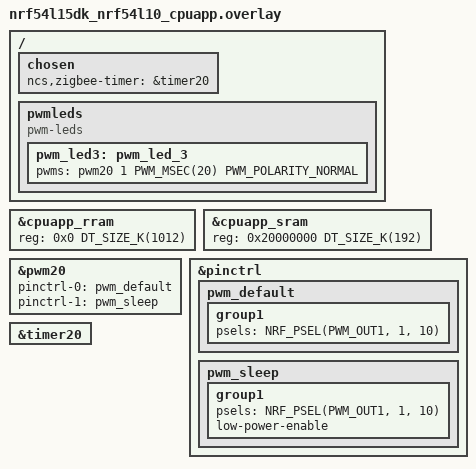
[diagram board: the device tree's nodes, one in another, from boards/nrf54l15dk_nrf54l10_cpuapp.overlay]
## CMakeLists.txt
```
#
# Copyright (c) 2024 Nordic Semiconductor ASA
#
# SPDX-License-Identifier: LicenseRef-Nordic-5-Clause
#

cmake_minimum_required(VERSION 3.20.0)

find_package(Zephyr REQUIRED HINTS $ENV{ZEPHYR_BASE})

project("Zigbee coordinator")

# NORDIC SDK APP START
target_sources(app PRIVATE
  src/main.c
  src/zboss_mem_globals.c
)

target_include_directories(app PRIVATE include)
# NORDIC SDK APP END

# LTO link: zb_memconfig.o from prebuilts is plain ELF (weak gc_*); strong gc_*
# in zb_mem_config_context.h must not be LTO bytecode or ld warns about symbol size.
if(CONFIG_LTO)
	set_source_files_properties(
		src/zboss_mem_globals.c
		PROPERTIES COMPILE_OPTIONS -fno-lto
	)
endif()
```

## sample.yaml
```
sample:
  description: Zigbee Light control - coordinator sample
  name: Zigbee Network coordinator
common:
  tags:
    - ci_build
    - smoke
    - sysbuild
    - ci_samples_zigbee
tests:
  sample.zigbee.network_coordinator:
    sysbuild: true
    build_only: true
    integration_platforms:
      - nrf5340dk/nrf5340/cpuapp
      - nrf54l15dk/nrf54l15/cpuapp
      - nrf54lc10dk/nrf54lc10a/cpuapp
      - nrf54lm20dk/nrf54lm20b/cpuapp
    platform_allow:
      - nrf52840dk/nrf52840
      - nrf5340dk/nrf5340/cpuapp
      - nrf54l15dk/nrf54l10/cpuapp
      - nrf54l15dk/nrf54l15/cpuapp
      - nrf54lc10dk/nrf54lc10a/cpuapp
      - nrf54lm20dk/nrf54lm20a/cpuapp
      - nrf54lm20dk/nrf54lm20b/cpuapp
  sample.zigbee.network_coordinator.demo_commissioning:
    sysbuild: true
    build_only: true
    extra_args:
      - SNIPPET=zigbee_demo_commissioning
    integration_platforms:
      - nrf54l15dk/nrf54l15/cpuapp
    platform_allow:
      - nrf52840dk/nrf52840
      - nrf5340dk/nrf5340/cpuapp
      - nrf54l15dk/nrf54l10/cpuapp
      - nrf54l15dk/nrf54l15/cpuapp
      - nrf54lc10dk/nrf54lc10a/cpuapp
      - nrf54lm20dk/nrf54lm20a/cpuapp
      - nrf54lm20dk/nrf54lm20b/cpuapp
```

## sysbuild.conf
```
#
# Copyright (c) 2026 Nordic Semiconductor ASA
#
# SPDX-License-Identifier: LicenseRef-Nordic-5-Clause
#

# Disable partition manager
SB_CONFIG_PARTITION_MANAGER=n
```

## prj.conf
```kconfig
#
# Copyright (c) 2024 Nordic Semiconductor ASA
#
# SPDX-License-Identifier: LicenseRef-Nordic-5-Clause
#

CONFIG_NCS_SAMPLES_DEFAULTS=y

CONFIG_UART_INTERRUPT_DRIVEN=y
CONFIG_SERIAL=y
CONFIG_GPIO=y

# Make sure printk is not printing to the UART console
CONFIG_CONSOLE=y
CONFIG_UART_CONSOLE=y

CONFIG_HEAP_MEM_POOL_SIZE=2048
CONFIG_MAIN_THREAD_PRIORITY=7

CONFIG_ZIGBEE_ADD_ON=y
CONFIG_ZIGBEE_APP_UTILS=y
CONFIG_ZIGBEE_ROLE_COORDINATOR=y

# Enable DK LED and Buttons library
CONFIG_DK_LIBRARY=y
```

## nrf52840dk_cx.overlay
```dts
/* Copyright (c) 2024 Nordic Semiconductor ASA
 *
 * SPDX-License-Identifier: LicenseRef-Nordic-5-Clause
 */

/ {
  radio_coex: radio_coex_three_wire {
    status = "okay";
    compatible = "generic-radio-coex-three-wire";
    req-gpios =     <&gpio0 14 (GPIO_PULL_DOWN | GPIO_ACTIVE_HIGH)>;
    pri-dir-gpios = <&gpio0 16 (GPIO_PULL_UP   | GPIO_ACTIVE_HIGH)>;
    grant-gpios =   <&gpio0 12 (GPIO_PULL_DOWN | GPIO_ACTIVE_HIGH)>;
  };
};

&radio {
  coex = <&radio_coex>;
};
```

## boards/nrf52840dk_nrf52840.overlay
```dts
/*
 * Copyright (c) 2024 Nordic Semiconductor ASA
 *
 * SPDX-License-Identifier: LicenseRef-Nordic-5-Clause
 */
/ {
	chosen {
		ncs,zigbee-timer = &timer2;
	};
};

&timer2 {
	status = "okay";
};
```

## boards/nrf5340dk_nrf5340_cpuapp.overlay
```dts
/*
 * Copyright (c) 2025 Nordic Semiconductor ASA
 *
 * SPDX-License-Identifier: LicenseRef-Nordic-5-Clause
 */

#include <nrf5340_cpuapp_partitions.dtsi>

/ {
	chosen {
		ncs,zigbee-timer = &timer2;
	};
};

&timer2 {
	status = "okay";
};
```

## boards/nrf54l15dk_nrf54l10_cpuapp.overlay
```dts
/*
 * Copyright (c) 2024 Nordic Semiconductor ASA
 *
 * SPDX-License-Identifier: LicenseRef-Nordic-5-Clause
 */


/ {

	chosen {
		ncs,zigbee-timer = &timer20;
	};

	pwmleds {
		compatible = "pwm-leds";
		pwm_led3: pwm_led_3 {
			pwms = <&pwm20 1 PWM_MSEC(20) PWM_POLARITY_NORMAL>;
		};
	};
};

// restore full RRAM and SRAM space - by default some parts are dedicated to FLPR
&cpuapp_rram {
	reg = <0x0 DT_SIZE_K(1012)>;
};

&cpuapp_sram {
	reg = <0x20000000 DT_SIZE_K(192)>;
	ranges = <0x0 0x20000000  DT_SIZE_K(192)>;
};

&pwm20 {
	status = "okay";
	pinctrl-0 = <&pwm_default>;
	pinctrl-1 = <&pwm_sleep>;
	pinctrl-names = "default", "sleep";
};

&pinctrl {
	pwm_default: pwm_default {
		group1 {
			psels = <NRF_PSEL(PWM_OUT1, 1, 10)>;
		};
	};
	pwm_sleep: pwm_sleep {
		group1 {
			psels = <NRF_PSEL(PWM_OUT1, 1, 10)>;
			low-power-enable;
		};
	};
};

&timer20 {
	status = "okay";
};
```

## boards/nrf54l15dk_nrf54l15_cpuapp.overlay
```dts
/*
 * Copyright (c) 2024 Nordic Semiconductor ASA
 *
 * SPDX-License-Identifier: LicenseRef-Nordic-5-Clause
 */

#include <nrf54l15_cpuapp_partitions.dtsi>

/ {
	chosen {
		ncs,zigbee-timer = &timer20;
	};

	pwmleds {
		compatible = "pwm-leds";

		pwm_led1: pwm_led_1 {
			pwms = <&pwm20 1 PWM_MSEC(20) PWM_POLARITY_NORMAL>;
		};
	};
};

&pwm20 {
	status = "okay";
	pinctrl-0 = <&pwm_default>;
	pinctrl-1 = <&pwm_sleep>;
	pinctrl-names = "default", "sleep";
};

&pinctrl {
	pwm_default: pwm_default {
		group1 {
			psels = <NRF_PSEL(PWM_OUT1, 1, 10)>;
		};
	};

	pwm_sleep: pwm_sleep {
		group1 {
			psels = <NRF_PSEL(PWM_OUT1, 1, 10)>;
			low-power-enable;
		};
	};
};

&timer20 {
	status = "okay";
};
```

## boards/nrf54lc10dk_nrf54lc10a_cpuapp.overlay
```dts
/*
 * Copyright (c) 2026 Nordic Semiconductor ASA
 *
 * SPDX-License-Identifier: LicenseRef-Nordic-5-Clause
 */

#include <nrf54lc10_cpuapp_partitions.dtsi>

/ {
	chosen {
		ncs,zigbee-timer = &timer20;
	};
};

&timer20 {
	status = "okay";
};
```

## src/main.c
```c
/*
 * Copyright (c) 2024 Nordic Semiconductor ASA
 *
 * SPDX-License-Identifier: LicenseRef-Nordic-5-Clause
 */

/** @file
 *  @brief Simple Zigbee network coordinator implementation
 */

#include <zephyr/kernel.h>
#include <zephyr/device.h>
#include <zephyr/logging/log.h>
#include <dk_buttons_and_leds.h>

#include <zboss_api.h>
#include <zigbee/zigbee_error_handler.h>
#include <zigbee/zigbee_app_utils.h>
#include <zigbee/zigbee_app_io_shell.h>
#include <zb_nrf_platform.h>


#define RUN_STATUS_LED                         DK_LED1
#define RUN_LED_BLINK_INTERVAL                 1000

/* Device endpoint, used to receive ZCL commands. */
#define ZIGBEE_COORDINATOR_ENDPOINT            10

/* Type of power sources available for the device.
 * For possible values see section 3.2.2.2.8 of ZCL specification.
 */
#define COORDINATOR_INIT_BASIC_POWER_SOURCE    ZB_ZCL_BASIC_POWER_SOURCE_DC_SOURCE

/* LED indicating that device successfully joined Zigbee network. */
#define ZIGBEE_NETWORK_STATE_LED               DK_LED3

/* LED used for device identification. */
#define IDENTIFY_LED                           DK_LED4

/* Button which reopens the Zigbee Network. */
#define KEY_ZIGBEE_NETWORK_REOPEN              DK_BTN1_MSK

/* Button used to enter the Identify mode. */
#define IDENTIFY_MODE_BUTTON                   DK_BTN4_MSK

/* If set to ZB_TRUE then device will not open the network after forming or reboot. */
#define ZIGBEE_MANUAL_STEERING                 ZB_FALSE

#define ZIGBEE_PERMIT_LEGACY_DEVICES           ZB_FALSE

#ifndef ZB_COORDINATOR_ROLE
#error Define ZB_COORDINATOR_ROLE to compile coordinator source code.
#endif

/* Button to start Factory Reset */
#define FACTORY_RESET_BUTTON IDENTIFY_MODE_BUTTON

LOG_MODULE_REGISTER(app, LOG_LEVEL_INF);

/* Main application customizable context.
 * Stores all settings and static values.
 */
struct zb_device_ctx {
	zb_zcl_basic_attrs_t basic_attr;
	zb_zcl_identify_attrs_t identify_attr;
};

/* Zigbee device application context storage. */
static struct zb_device_ctx dev_ctx;

ZB_ZCL_DECLARE_IDENTIFY_ATTRIB_LIST(
	identify_attr_list,
	&dev_ctx.identify_attr.identify_time);

ZB_ZCL_DECLARE_BASIC_ATTRIB_LIST(
	basic_attr_list,
	&dev_ctx.basic_attr.zcl_version,
	&dev_ctx.basic_attr.power_source);

ZB_HA_DECLARE_RANGE_EXTENDER_CLUSTER_LIST(
	nwk_coordinator_clusters,
	basic_attr_list,
	identify_attr_list);

ZB_HA_DECLARE_RANGE_EXTENDER_EP(
	nwk_coordinator_ep,
	ZIGBEE_COORDINATOR_ENDPOINT,
	nwk_coordinator_clusters);

ZBOSS_DECLARE_DEVICE_CTX_1_EP(
	nwk_coordinator,
	nwk_coordinator_ep);


/**@brief Function for initializing all clusters attributes. */
static void app_clusters_attr_init(void)
{
	/* Basic cluster attributes data. */
	dev_ctx.basic_attr.zcl_version = ZB_ZCL_VERSION;
	dev_ctx.basic_attr.power_source = COORDINATOR_INIT_BASIC_POWER_SOURCE;

	/* Identify cluster attributes data. */
	dev_ctx.identify_attr.identify_time = ZB_ZCL_IDENTIFY_IDENTIFY_TIME_DEFAULT_VALUE;
}

/**@brief Function to toggle the identify LED.
 *
 * @param  param  Callback parameter, required by ZBOSS scheduler API.
 */
static void toggle_identify_led(zb_cb_param_t param)
{
	static int blink_status;

	zigbee_app_io_set_led(IDENTIFY_LED, (++blink_status) % 2);
	ZB_SCHEDULE_APP_ALARM(toggle_identify_led, param, ZB_MILLISECONDS_TO_BEACON_INTERVAL(100));
}

/**@brief Function to handle identify notification events on the first endpoint.
 *
 * @param  param  ZB_TRUE when identify starts, ZB_FALSE when it stops.
 */
static void identify_cb(zb_cb_param_t param)
{
	zb_ret_t zb_err_code;

	if (param) {
		/* Schedule a self-scheduling function that will toggle the LED. */
		ZB_SCHEDULE_APP_CALLBACK(toggle_identify_led, param);
	} else {
		/* Cancel the toggling function alarm and turn off LED. */
		zb_err_code = ZB_SCHEDULE_APP_ALARM_CANCEL(toggle_identify_led, ZB_ALARM_ANY_PARAM);
		ZVUNUSED(zb_err_code);

		zigbee_app_io_set_led(IDENTIFY_LED, 0);
	}
}

/**@brief Starts identifying the device.
 *
 * @param  param  Unused parameter, required by ZBOSS scheduler API.
 */
static void start_identifying(zb_cb_param_t param)
{
	ZVUNUSED(param);

	if (ZB_JOINED()) {
		/* Check if endpoint is in identifying mode,
		 * if not, put desired endpoint in identifying mode.
		 */
		if (dev_ctx.identify_attr.identify_time ==
		    ZB_ZCL_IDENTIFY_IDENTIFY_TIME_DEFAULT_VALUE) {

			zb_ret_t zb_err_code = zb_bdb_finding_binding_target(
				ZIGBEE_COORDINATOR_ENDPOINT);

			if (zb_err_code == RET_OK) {
				LOG_INF("Enter identify mode");
			} else if (zb_err_code == RET_INVALID_STATE) {
				LOG_WRN("RET_INVALID_STATE - Cannot enter identify mode");
			} else {
				ZB_ERROR_CHECK(zb_err_code);
			}
		} else {
			LOG_INF("Cancel identify mode");
			zb_bdb_finding_binding_target_cancel();
		}
	} else {
		LOG_WRN("Device not in a network - cannot enter identify mode");
	}
}

/**@brief Callback used in order to visualise network steering period.
 *
 * @param[in]   param   Not used. Required by callback type definition.
 */
static void steering_finished(zb_cb_param_t param)
{
	ARG_UNUSED(param);

	LOG_INF("Network steering finished");
	zigbee_app_io_set_led_off(ZIGBEE_NETWORK_STATE_LED);
}

/**@brief Callback for button events.
 *
 * @param[in]   button_state  Bitmask containing buttons state.
 * @param[in]   has_changed   Bitmask containing buttons that has changed their state.
 */
static void button_changed(uint32_t button_state, uint32_t has_changed)
{
	/* Calculate bitmask of buttons that are pressed and have changed their state. */
	uint32_t buttons = button_state & has_changed;
	zb_bool_t comm_status;

	if (buttons & KEY_ZIGBEE_NETWORK_REOPEN) {
		(void)(ZB_SCHEDULE_APP_ALARM_CANCEL(steering_finished, ZB_ALARM_ANY_PARAM));

		comm_status = bdb_start_top_level_commissioning(ZB_BDB_NETWORK_STEERING);
		if (comm_status) {
			LOG_INF("Top level commissioning restated");
		} else {
			LOG_INF("Top level commissioning hasn't finished yet!");
		}
	}

	if (IDENTIFY_MODE_BUTTON & has_changed) {
		if (IDENTIFY_MODE_BUTTON & button_state) {
			/* Button changed its state to pressed */
		} else {
			/* Button changed its state to released */
			if (was_factory_reset_done()) {
				/* The long press was for Factory Reset */
				LOG_DBG("After Factory Reset - ignore button release");
			} else   {
				/* Button released before Factory Reset */

				/* Start identification mode */
				ZB_SCHEDULE_APP_CALLBACK(start_identifying, 0);
			}
		}
	}

	check_factory_reset_button(button_state, has_changed);
}

/**@brief Function for initializing LEDs and Buttons. */
static void configure_gpio(void)
{
	int err;

	err = dk_buttons_init(button_changed);
	if (err) {
		LOG_ERR("Cannot init buttons (err: %d)", err);
	}

	err = dk_leds_init();
	if (err) {
		LOG_ERR("Cannot init LEDs (err: %d)", err);
	}

	zigbee_app_io_shell_init(button_changed);
}

/**@brief Zigbee stack event handler.
 *
 * @param[in]   param   Reference to the Zigbee stack buffer used to pass signal.
 */
void zboss_signal_handler(zb_cb_param_t param)
{
	/* Read signal description out of memory buffer. */
	zb_zdo_app_signal_hdr_t *sg_p = NULL;
	zb_zdo_app_signal_type_t sig = zb_get_app_signal(param, &sg_p);
	zb_ret_t status = ZB_GET_APP_SIGNAL_STATUS(param);
	zb_ret_t zb_err_code;
	zb_bool_t comm_status;
	zb_time_t timeout_bi;

	switch (sig) {
	case ZB_BDB_SIGNAL_DEVICE_REBOOT:
		/* BDB initialization completed after device reboot,
		 * use NVRAM contents during initialization.
		 * Device joined/rejoined and started.
		 */
		if (status == RET_OK) {
			if (ZIGBEE_MANUAL_STEERING == ZB_FALSE) {
				LOG_INF("Start network steering");
				comm_status = bdb_start_top_level_commissioning(
					ZB_BDB_NETWORK_STEERING);
				ZB_COMM_STATUS_CHECK(comm_status);
			} else {
				LOG_INF("Coordinator restarted successfully");
			}
		} else {
			LOG_ERR("Failed to initialize Zigbee stack using NVRAM data (status: %d)",
				status);
		}
		break;

	case ZB_BDB_SIGNAL_STEERING:
		if (status == RET_OK) {
			if (ZIGBEE_PERMIT_LEGACY_DEVICES == ZB_TRUE) {
				LOG_INF("Allow pre-Zigbee 3.0 devices to join the network");
				zb_bdb_set_legacy_device_support(1);
			}

			/* Schedule an alarm to notify about the end of steering period.
			 */
			LOG_INF("Network steering started");
			zb_err_code = ZB_SCHEDULE_APP_ALARM(
				steering_finished, 0,
				ZB_TIME_ONE_SECOND *
				ZB_ZGP_DEFAULT_COMMISSIONING_WINDOW);
			ZB_ERROR_CHECK(zb_err_code);
		}
		break;

	case ZB_ZDO_SIGNAL_DEVICE_ANNCE: {
		zb_zdo_signal_device_annce_params_t *dev_annce_params =
			ZB_ZDO_SIGNAL_GET_PARAMS(
				sg_p, zb_zdo_signal_device_annce_params_t);

		LOG_INF("New device commissioned or rejoined (short: 0x%04hx)",
			dev_annce_params->device_short_addr);

		zb_err_code = ZB_SCHEDULE_APP_ALARM_CANCEL(steering_finished, ZB_ALARM_ANY_PARAM);
		if (zb_err_code == RET_OK) {
			LOG_INF("Joining period extended.");
			zb_err_code = ZB_SCHEDULE_APP_ALARM(
				steering_finished, 0,
				ZB_TIME_ONE_SECOND *
				ZB_ZGP_DEFAULT_COMMISSIONING_WINDOW);
			ZB_ERROR_CHECK(zb_err_code);
		}
	} break;

	default:
		/* Call default signal handler. */
		ZB_ERROR_CHECK(zigbee_default_signal_handler(param));
		break;
	}

	/* Update network status LED. */
	if (ZB_JOINED() &&
	    (ZB_SCHEDULE_GET_ALARM_TIME(steering_finished, ZB_ALARM_ANY_PARAM,
					&timeout_bi) == RET_OK)) {
		zigbee_app_io_set_led_on(ZIGBEE_NETWORK_STATE_LED);
	} else {
		zigbee_app_io_set_led_off(ZIGBEE_NETWORK_STATE_LED);
	}

	/*
	 * All callbacks should either reuse or free passed buffers.
	 * If param == 0, the buffer is invalid (not passed).
	 */
	if (param) {
		zb_buf_free(param);
	}
}

int main(void)
{
	int blink_status = 0;

	LOG_INF("Starting Zigbee R23 Network Coordinator application");

	/* Initialize */
	configure_gpio();
	register_factory_reset_button(FACTORY_RESET_BUTTON);

	/* Register device context (endpoints). */
	ZB_AF_REGISTER_DEVICE_CTX(&nwk_coordinator);

	app_clusters_attr_init();

	/* Register handlers to identify notifications. */
	ZB_AF_SET_IDENTIFY_NOTIFICATION_HANDLER(ZIGBEE_COORDINATOR_ENDPOINT, identify_cb);

	/* Start Zigbee default thread */
	zigbee_enable();

	LOG_INF("Zigbee R23 Network Coordinator application started");

	while (1) {
		zigbee_app_io_set_led(RUN_STATUS_LED, (++blink_status) % 2);
		k_sleep(K_MSEC(RUN_LED_BLINK_INTERVAL));
	}
}
```

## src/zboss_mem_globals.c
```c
/*
 * Copyright (c) 2026 Nordic Semiconductor ASA
 *
 * SPDX-License-Identifier: LicenseRef-Nordic-5-Clause
 */

/**
 * @file zboss_mem_globals.c
 *
 * Holds ZBOSS configurable RAM globals (via zb_mem_config_context.h) in a
 * dedicated translation unit. When linking LTO-built prebuilt libzboss with
 * CONFIG_LTO, zb_memconfig.c in the archive is built with -fno-lto (weak
 * defaults); defining the strong gc_* arrays in another LTO-compiled file
 * triggers ld "size of symbol ... changed" warnings. Compiling this file
 * with -fno-lto keeps weak + strong resolution in the classic ELF path.
 */

#include <zboss_api.h>
#include <zb_mem_config_max.h>
```
